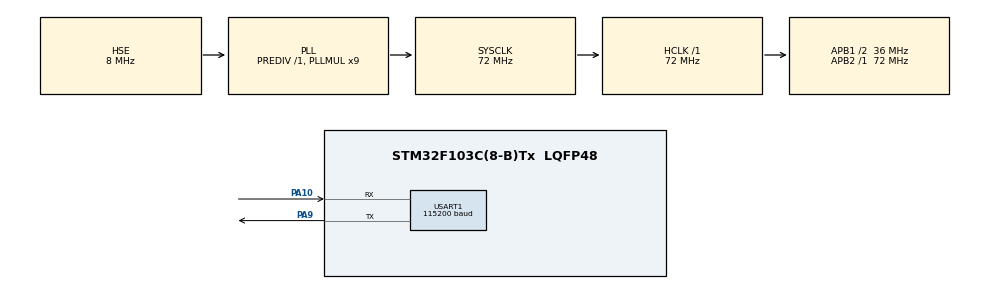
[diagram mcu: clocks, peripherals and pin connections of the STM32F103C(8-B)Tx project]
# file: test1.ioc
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Mcu.Family=STM32F1
Mcu.Name=STM32F103C(8-B)Tx
Mcu.Package=LQFP48
NVIC.PriorityGroup=NVIC_PRIORITYGROUP_4
NVIC.TIM1_BRK_IRQn=true\:0\:0\:false\:false\:true\:true\:true\:true
NVIC.TIM1_CC_IRQn=true\:0\:0\:false\:false\:true\:true\:true\:true
NVIC.TIM1_TRG_COM_IRQn=true\:0\:0\:false\:false\:true\:true\:true\:true
NVIC.TIM1_UP_IRQn=true\:1\:0\:true\:false\:true\:true\:true\:true
NVIC.USART1_IRQn=true\:0\:0\:false\:false\:true\:true\:true\:true
PA10.Mode=Asynchronous
PA10.Signal=USART1_RX
PA13.Mode=Serial_Wire
PA13.Signal=SYS_JTMS-SWDIO
PA14.Mode=Serial_Wire
PA14.Signal=SYS_JTCK-SWCLK
PA9.Mode=Asynchronous
PA9.Signal=USART1_TX
PD0-OSC_IN.Mode=HSE-External-Oscillator
PD0-OSC_IN.Signal=RCC_OSC_IN
PD1-OSC_OUT.Mode=HSE-External-Oscillator
PD1-OSC_OUT.Signal=RCC_OSC_OUT
ProjectManager.HeapSize=0x200
ProjectManager.StackSize=0x400
ProjectManager.TargetToolchain=MDK-ARM V5.32
RCC.AHBFreq_Value=72000000
RCC.APB1CLKDivider=RCC_HCLK_DIV2
RCC.APB1Freq_Value=36000000
RCC.APB1TimFreq_Value=72000000
RCC.APB2Freq_Value=72000000
RCC.APB2TimFreq_Value=72000000
RCC.HCLKFreq_Value=72000000
RCC.PLLMUL=RCC_PLL_MUL9
RCC.PLLSourceVirtual=RCC_PLLSOURCE_HSE
RCC.SYSCLKFreq_VALUE=72000000
RCC.SYSCLKSource=RCC_SYSCLKSOURCE_PLLCLK
RCC.USBFreq_Value=72000000
TIM1.Period=1
TIM1.Prescaler=800-1
USART1.BaudRate=115200
USART1.VirtualMode=VM_ASYNC
VP_TIM1_VS_ClockSourceINT.Mode=Internal
VP_TIM1_VS_ClockSourceITR.Mode=TriggerSource_ITR0
board=custom

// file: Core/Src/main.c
/* USER CODE BEGIN Header */
/**
  ******************************************************************************
  * @file           : main.c
  * @brief          : Main program body
  ******************************************************************************
  * @attention
  *
  * Copyright (c) 2025 STMicroelectronics.
  * All rights reserved.
  *
  * This software is licensed under terms that can be found in the LICENSE file
  * in the root directory of this software component.
  * If no LICENSE file comes with this software, it is provided AS-IS.
  *
  ******************************************************************************
  */
/* USER CODE END Header */
#include "main.h"
#include "tim.h"
#include "usart.h"
#include "gpio.h"

/* USER CODE BEGIN Includes */
#include "m66.h"
#include <stdio.h>
#include <string.h>
#include <stdint.h>
#include <stddef.h>
#include <stdbool.h>
/* USER CODE END Includes */

/* USER CODE BEGIN PV */
/* ????????? ?? ?? ISR ????? ??????? ???? volatile ????? */
volatile uint32_t sm = 0; /* ????????? ??? ????? (ms) */
volatile int sd = 0;
volatile int sp = 0;
/* USER CODE END PV */

void SystemClock_Config(void);

/* USER CODE BEGIN 0 */

/* ??????? ?? ??? strlen ????????? (?? ???? ????) */
size_t my_strlen(const char *str)
{
    size_t len = 0;
    if (str == NULL) return 0;
    while (str[len] != '\0')
    {
        len++;
    }
    return len;
}

/* ???????? ???????? ??? */
bool compare_arrays(const char *arr1, const char *arr2, size_t len)
{
    if (!arr1 || !arr2) return false;

    for (size_t i = 0; i < len; i++) {
        if (arr1[i] != arr2[i]) return false;
    }

    return true;
}

/* callback HAL ???? ????? ?????? ????? */
/* ??? ??? TIM1 ???? ????? ??? ?? ?? 1ms ??? ??? (PSC/ARR ????? tim.c ????? ???) */
void HAL_TIM_PeriodElapsedCallback(TIM_HandleTypeDef *htim)
{
  if (htim->Instance == TIM1)
  {
    sm++; /* ?? ???????? � 1 ms */
  }
}
/* USER CODE END 0 */

int main(void)
{

  /* MCU Configuration--------------------------------------------------------*/

  /* Reset of all peripherals, Initializes the Flash interface and the Systick. */
  HAL_Init();

  /* Configure the system clock */
  SystemClock_Config();

  /* Initialize all configured peripherals */
  MX_GPIO_Init();
  MX_USART1_UART_Init();
  MX_TIM1_Init();
  /* USER CODE BEGIN 2 */

  /* ???????? ????? M66 */
  m66_init(&huart1);

  /* ????? ????? SMS (?? ???? ???? ?? ?? ????? ????) */
  m66_sms_send("1234", "+989918555384");

  /* USER CODE END 2 */

  /* Infinite loop */
  /* USER CODE BEGIN WHILE */
  uint32_t last_ms = 0;
  while (1)
  {
    /* Toggle LED ?? 1000 ms ?? ???? sm (?? ?? ISR ?????? ???????) */
    if ((sm - last_ms) >= 1000)
    {
      last_ms += 1000;
      HAL_GPIO_TogglePin(GPIOC, GPIO_PIN_13);
    }

    /* ?????? ?????? SMS */
    if (m66_sms_received_flag)
    {
      m66_sms_read();
      m66_sms_received_flag = 0;

      /* ???? ??????? ???? ?? ???? ???? */
      sm = 0;
      last_ms = 0;

      /* ???? ????????: ??? ????? ???? ???? ?? ??????? */
      m66_sms_send(m66_sms_inbox_message, m66_sms_sender_number);
    }

    /* ?? ???? ???? ?? HAL_Delay(1) ???? ???? ???? CPU ??????? ????:
       HAL_Delay(1); */
  }
    /* USER CODE END WHILE */

}

void SystemClock_Config(void)
{
  RCC_OscInitTypeDef RCC_OscInitStruct = {0};
  RCC_ClkInitTypeDef RCC_ClkInitStruct = {0};

  /** Initializes the RCC Oscillators according to the specified parameters
  * in the RCC_OscInitTypeDef structure.
  */
  RCC_OscInitStruct.OscillatorType = RCC_OSCILLATORTYPE_HSE;
  RCC_OscInitStruct.HSEState = RCC_HSE_ON;
  RCC_OscInitStruct.HSEPredivValue = RCC_HSE_PREDIV_DIV1;
  RCC_OscInitStruct.HSIState = RCC_HSI_ON;
  RCC_OscInitStruct.PLL.PLLState = RCC_PLL_ON;
  RCC_OscInitStruct.PLL.PLLSource = RCC_PLLSOURCE_HSE;
  RCC_OscInitStruct.PLL.PLLMUL = RCC_PLL_MUL9;
  if (HAL_RCC_OscConfig(&RCC_OscInitStruct) != HAL_OK)
  {
    Error_Handler();
  }

  /** Initializes the CPU, AHB and APB buses clocks
  */
  RCC_ClkInitStruct.ClockType = RCC_CLOCKTYPE_HCLK|RCC_CLOCKTYPE_SYSCLK
                              |RCC_CLOCKTYPE_PCLK1|RCC_CLOCKTYPE_PCLK2;
  RCC_ClkInitStruct.SYSCLKSource = RCC_SYSCLKSOURCE_PLLCLK;
  RCC_ClkInitStruct.AHBCLKDivider = RCC_SYSCLK_DIV1;
  RCC_ClkInitStruct.APB1CLKDivider = RCC_HCLK_DIV2;
  RCC_ClkInitStruct.APB2CLKDivider = RCC_HCLK_DIV1;

  if (HAL_RCC_ClockConfig(&RCC_ClkInitStruct, FLASH_LATENCY_2) != HAL_OK)
  {
    Error_Handler();
  }
}

void Error_Handler(void)
{
  __disable_irq();
  while (1)
  {
  }
}

#ifdef  USE_FULL_ASSERT
/**
  * @brief  Reports the name of the source file and the source line number
  *         where the assert_param error has occurred.
  * @param  file: pointer to the source file name
  * @param  line: assert_param error line source number
  * @retval None
  */
void assert_failed(uint8_t *file, uint32_t line)
{
  /* USER CODE BEGIN 6 */
  /* ????????? ????? ??? printf ??????? ?? ????? ?? ?????? */
  /* USER CODE END 6 */
}
#endif /* USE_FULL_ASSERT */
